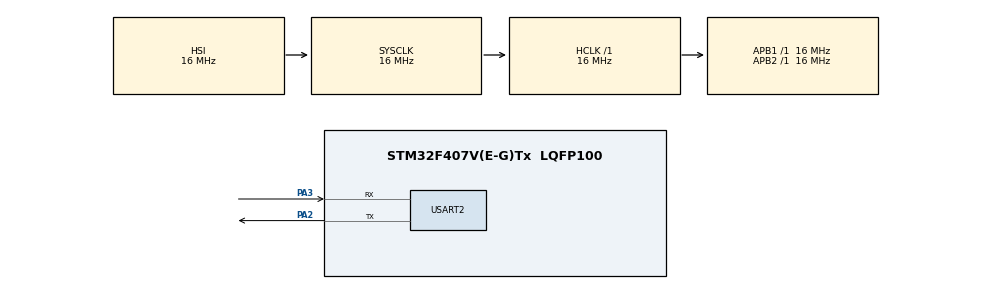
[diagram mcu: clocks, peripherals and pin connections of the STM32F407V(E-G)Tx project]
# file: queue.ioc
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FREERTOS.Tasks01=defaultTask,0,128,StartDefaultTask,Default,NULL,Dynamic,NULL,NULL
Mcu.Family=STM32F4
Mcu.Name=STM32F407V(E-G)Tx
Mcu.Package=LQFP100
NVIC.PriorityGroup=NVIC_PRIORITYGROUP_4
NVIC.TIM6_DAC_IRQn=true\:15\:0\:false\:false\:true\:false\:false\:true
NVIC.TimeBase=TIM6_DAC_IRQn
NVIC.TimeBaseIP=TIM6
NVIC.USART2_IRQn=true\:5\:0\:false\:false\:true\:true\:true\:true
PA2.Mode=Asynchronous
PA2.Signal=USART2_TX
PA3.Mode=Asynchronous
PA3.Signal=USART2_RX
PH0-OSC_IN.Mode=HSE-External-Oscillator
PH0-OSC_IN.Signal=RCC_OSC_IN
PH1-OSC_OUT.Mode=HSE-External-Oscillator
PH1-OSC_OUT.Signal=RCC_OSC_OUT
ProjectManager.HeapSize=0x200
ProjectManager.StackSize=0x400
ProjectManager.TargetToolchain=STM32CubeIDE
RCC.AHBFreq_Value=16000000
RCC.APB1Freq_Value=16000000
RCC.APB2Freq_Value=16000000
RCC.CortexFreq_Value=16000000
RCC.HSE_VALUE=25000000
RCC.HSI_VALUE=16000000
RCC.LSE_VALUE=32768
RCC.SYSCLKFreq_VALUE=16000000
RCC.VCOOutputFreq_Value=192000000
USART2.VirtualMode=VM_ASYNC
VP_FREERTOS_VS_CMSIS_V1.Mode=CMSIS_V1
VP_SYS_VS_tim6.Mode=TIM6
board=custom

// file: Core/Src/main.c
/* USER CODE BEGIN Header */
/**
  ******************************************************************************
  * @file           : main.c
  * @brief          : Main program body
  ******************************************************************************
  * @attention
  *
  * <h2><center>&copy; Copyright (c) 2021 STMicroelectronics.
  * All rights reserved.</center></h2>
  *
  * This software component is licensed by ST under BSD 3-Clause license,
  * the "License"; You may not use this file except in compliance with the
  * License. You may obtain a copy of the License at:
  *                        opensource.org/licenses/BSD-3-Clause
  *
  ******************************************************************************
  */
/* USER CODE END Header */
#include "main.h"
//#include "cmsis_os.h"

/* USER CODE BEGIN Includes */
#include "FreeRTOS.h"
#include "task.h"
#include "timers.h"
#include "queue.h"
#include "semphr.h"
#include "event_groups.h"
#include "string.h"
#include "stdio.h"
/* USER CODE END Includes */

UART_HandleTypeDef huart2;

//osThreadId defaultTaskHandle;

void SystemClock_Config(void);
static void MX_GPIO_Init(void);
static void MX_USART2_UART_Init(void);
//void StartDefaultTask(void const * argument);

/* USER CODE BEGIN 0 */
//Task Handle
xTaskHandle Sender_HPT_Handle;
xTaskHandle Sender_LPT_Handle;
xTaskHandle Receiver_Handle;
// Queue
xQueueHandle SimpleQueue;
//task function
void Sender_HPT_Task(void *argument);
void Sender_LPT_Task(void *argument);
void Receiver_Task(void *argument);

uint8_t rx_data;
/* USER CODE END 0 */

int main(void)
{

  /* MCU Configuration--------------------------------------------------------*/

  /* Reset of all peripherals, Initializes the Flash interface and the Systick. */
  HAL_Init();

  /* Configure the system clock */
  SystemClock_Config();

  /* Initialize all configured peripherals */
  MX_GPIO_Init();
  MX_USART2_UART_Init();
  /* USER CODE BEGIN 2 */

  /***********Creaet Interger Queue*********/
  HAL_UART_Receive_IT(&huart2, &rx_data, 1);
  SimpleQueue = xQueueCreate(5,sizeof(int));
  if(SimpleQueue == 0)//queue not create
  {
	  char *str="Unable to create integer queue\n\n";
	  HAL_UART_Transmit(&huart2, (uint8_t*)str, strlen(str), HAL_MAX_DELAY);
  }
  else
  {
	  char *str = "Integer Queue Created Successfully\n\n";
	  HAL_UART_Transmit(&huart2, (uint8_t*)str, strlen(str), HAL_MAX_DELAY);
  }

  /**************** Task Related ************** */
  xTaskCreate(Sender_HPT_Task, "HPT_Send", 128, NULL, 3, &Sender_HPT_Handle);
  xTaskCreate(Sender_LPT_Task, "LPT_Send", 128, (void *)111, 2, &Sender_LPT_Handle);
  xTaskCreate(Receiver_Task, "Receiver", 128, NULL, 1, &Receiver_Handle);

  //HAL_UART_Receive_IT(&huart2, &rx_data, 1);

  vTaskStartScheduler();
  /* USER CODE END 2 */

  /* Create the thread(s) */
  /* definition and creation of defaultTask */
//  osThreadDef(defaultTask, StartDefaultTask, osPriorityNormal, 0, 128);
//  defaultTaskHandle = osThreadCreate(osThread(defaultTask), NULL);

  /* Start scheduler */
//  osKernelStart();

  /* We should never get here as control is now taken by the scheduler */
  /* Infinite loop */
  while (1)
  {

  }
}

void SystemClock_Config(void)
{
  RCC_OscInitTypeDef RCC_OscInitStruct = {0};
  RCC_ClkInitTypeDef RCC_ClkInitStruct = {0};

  /** Configure the main internal regulator output voltage
  */
  __HAL_RCC_PWR_CLK_ENABLE();
  __HAL_PWR_VOLTAGESCALING_CONFIG(PWR_REGULATOR_VOLTAGE_SCALE1);
  /** Initializes the RCC Oscillators according to the specified parameters
  * in the RCC_OscInitTypeDef structure.
  */
  RCC_OscInitStruct.OscillatorType = RCC_OSCILLATORTYPE_HSI;
  RCC_OscInitStruct.HSIState = RCC_HSI_ON;
  RCC_OscInitStruct.HSICalibrationValue = RCC_HSICALIBRATION_DEFAULT;
  RCC_OscInitStruct.PLL.PLLState = RCC_PLL_NONE;
  if (HAL_RCC_OscConfig(&RCC_OscInitStruct) != HAL_OK)
  {
    Error_Handler();
  }
  /** Initializes the CPU, AHB and APB buses clocks
  */
  RCC_ClkInitStruct.ClockType = RCC_CLOCKTYPE_HCLK|RCC_CLOCKTYPE_SYSCLK
                              |RCC_CLOCKTYPE_PCLK1|RCC_CLOCKTYPE_PCLK2;
  RCC_ClkInitStruct.SYSCLKSource = RCC_SYSCLKSOURCE_HSI;
  RCC_ClkInitStruct.AHBCLKDivider = RCC_SYSCLK_DIV1;
  RCC_ClkInitStruct.APB1CLKDivider = RCC_HCLK_DIV1;
  RCC_ClkInitStruct.APB2CLKDivider = RCC_HCLK_DIV1;

  if (HAL_RCC_ClockConfig(&RCC_ClkInitStruct, FLASH_LATENCY_0) != HAL_OK)
  {
    Error_Handler();
  }
}

static void MX_USART2_UART_Init(void)
{

  huart2.Instance = USART2;
  huart2.Init.BaudRate = 115200;
  huart2.Init.WordLength = UART_WORDLENGTH_8B;
  huart2.Init.StopBits = UART_STOPBITS_1;
  huart2.Init.Parity = UART_PARITY_NONE;
  huart2.Init.Mode = UART_MODE_TX_RX;
  huart2.Init.HwFlowCtl = UART_HWCONTROL_NONE;
  huart2.Init.OverSampling = UART_OVERSAMPLING_16;
  if (HAL_UART_Init(&huart2) != HAL_OK)
  {
    Error_Handler();
  }

}

static void MX_GPIO_Init(void)
{

  /* GPIO Ports Clock Enable */
  __HAL_RCC_GPIOH_CLK_ENABLE();
  __HAL_RCC_GPIOA_CLK_ENABLE();

}

/* USER CODE BEGIN 4 */
void Sender_HPT_Task (void *argument)
{
	int i=222;
	uint32_t TickDelay = pdMS_TO_TICKS(2000);
	while (1)
	{
		char *str = "Entered Sender_HTP Task\n about to send a number to queue\n\n";
		HAL_UART_Transmit(&huart2, (uint8_t *)str, strlen (str), HAL_MAX_DELAY);
		if (xQueueSend(SimpleQueue, &i, portMAX_DELAY) == pdPASS)
		{
			char *str2 = " Successfully sent the number to the queue\nLeaving SENDER_HPT Task\n\n\n";
			HAL_UART_Transmit(&huart2, (uint8_t *)str2, strlen (str2), HAL_MAX_DELAY);
		}
		vTaskDelay(TickDelay);
	}
}

void Sender_LPT_Task (void *argument)
{
	int ToSend;
	uint32_t TickDelay = pdMS_TO_TICKS(1000);
	while (1)
	{
		ToSend = (int) argument;
		char *str = "Entered Sender_LTP Task\n about to send a number to queue\n\n";
		HAL_UART_Transmit(&huart2, (uint8_t *)str, strlen (str), HAL_MAX_DELAY);
		xQueueSend(SimpleQueue,&ToSend,portMAX_DELAY);

		char *str2 = " Successfully sent the number to the queue\nLeaving SENDER_LPT Task\n\n\n";
		HAL_UART_Transmit(&huart2, (uint8_t *)str2, strlen (str2), HAL_MAX_DELAY);

		vTaskDelay(TickDelay);
	}
}

void Receiver_Task (void *argument)
{
	int received=0;
	uint32_t TickDelay = pdMS_TO_TICKS(5000);
	while (1)
	{
		char str[100];
		strcpy(str,"Entered Receive Task\n about to receive a number from the queue\n\n");
		HAL_UART_Transmit(&huart2, (uint8_t *)str, strlen (str), HAL_MAX_DELAY);
		if (xQueueReceive(SimpleQueue, &received, portMAX_DELAY) != pdTRUE)
		{
			HAL_UART_Transmit(&huart2, (uint8_t *)"Error in Receiving from Queue\n\n", 31, 1000);
		}
		else
		{
			sprintf(str, " Successfully RECEIVED the number %d to the queue\nLeaving RECEIVER Task\n\n\n",received);
			HAL_UART_Transmit(&huart2, (uint8_t *)str, strlen (str), HAL_MAX_DELAY);
		}
		vTaskDelay(TickDelay);
	}
}

void HAL_UART_RxCpltCallback(UART_HandleTypeDef *huart)
{
	int ToSend = 123456789;
	if (rx_data == 'r')
	{
		 /* The xHigherPriorityTaskWoken parameter must be initialized to pdFALSE as
		 it will get set to pdTRUE inside the interrupt safe API function if a
		 context switch is required. */
		BaseType_t xHigherPriorityTaskWoken = pdFALSE;
		char *str = "\n\nInterrupt\n\n";
		HAL_UART_Transmit(huart, (uint8_t *)str, strlen(str), 500);

		if (xQueueSendToFrontFromISR(SimpleQueue, &ToSend, &xHigherPriorityTaskWoken) == pdPASS)
		{
			str = "\n\nSent from ISR\n\n";
			HAL_UART_Transmit(huart, (uint8_t *)str, strlen(str), 500);
		}

		/* Pass the xHigherPriorityTaskWoken value into portEND_SWITCHING_ISR(). If
		 xHigherPriorityTaskWoken was set to pdTRUE inside xSemaphoreGiveFromISR()
		 then calling portEND_SWITCHING_ISR() will request a context switch. If
		 xHigherPriorityTaskWoken is still pdFALSE then calling
		 portEND_SWITCHING_ISR() will have no effect */

		portEND_SWITCHING_ISR(xHigherPriorityTaskWoken);
	}
	HAL_UART_Receive_IT(&huart2, &rx_data, 1);
}
/* USER CODE END 4 */

//void StartDefaultTask(void const * argument)
//{
//  /* USER CODE BEGIN 5 */
//  /* Infinite loop */
//  for(;;)
//  {
//    osDelay(1);
//  }
//  /* USER CODE END 5 */
//}

void HAL_TIM_PeriodElapsedCallback(TIM_HandleTypeDef *htim)
{
  if (htim->Instance == TIM6) {
    HAL_IncTick();
  }
}

void Error_Handler(void)
{
  __disable_irq();
  while (1)
  {
  }
}

/************************ (C) COPYRIGHT STMicroelectronics *****END OF FILE****/
